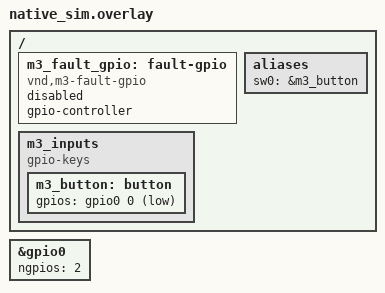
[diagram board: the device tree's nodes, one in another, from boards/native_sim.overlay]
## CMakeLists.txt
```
cmake_minimum_required(VERSION 3.20.0)
find_package(Zephyr REQUIRED HINTS $ENV{ZEPHYR_BASE})
project(crux_m3_native_tests LANGUAGES C)
if(NOT M3_GPIO_SCENARIO MATCHES "^(emulated|missing|fault)$")
    message(FATAL_ERROR "Select an explicit M3_GPIO_SCENARIO")
endif()
target_compile_definitions(app PRIVATE
    M3_EXPECT_MISSING=$<STREQUAL:${M3_GPIO_SCENARIO},missing>
    M3_EXPECT_READ_ERROR=$<STREQUAL:${M3_GPIO_SCENARIO},fault>)
target_sources(app PRIVATE src/main.c src/fault_gpio.c
    ../../samples/controller/core/health.c
    ../../samples/controller/zephyr/device_input.c)
target_include_directories(app PRIVATE ../../samples/controller/include
    ../../samples/controller/zephyr .)
target_compile_options(app PRIVATE -Wall -Wextra -Werror)
```

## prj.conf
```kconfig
CONFIG_STD_C17=y
CONFIG_ZTEST=y
CONFIG_GPIO=y
```

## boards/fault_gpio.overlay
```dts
&m3_fault_gpio {
    status = "okay";
};
&m3_button {
    gpios = <&m3_fault_gpio 0 GPIO_ACTIVE_LOW>;
};
```

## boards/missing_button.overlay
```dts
/ {
    /delete-node/ m3_inputs;
    aliases {
        /delete-property/ sw0;
    };
};
```

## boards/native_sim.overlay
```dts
#include <zephyr/dt-bindings/gpio/gpio.h>

/ {
    m3_fault_gpio: fault-gpio {
        compatible = "vnd,m3-fault-gpio";
        gpio-controller;
        #gpio-cells = <2>;
        status = "disabled";
    };
    aliases {
        sw0 = &m3_button;
    };
    m3_inputs {
        compatible = "gpio-keys";
        m3_button: button {
            gpios = <&gpio0 0 (GPIO_PULL_UP | GPIO_ACTIVE_LOW)>;
        };
    };
};

&gpio0 {
    ngpios = <2>;
};
```

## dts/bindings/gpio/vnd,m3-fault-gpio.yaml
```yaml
description: Test-only GPIO API fixture for a controlled negative native read
compatible: "vnd,m3-fault-gpio"
include: gpio-controller.yaml
gpio-cells:
  - pin
  - flags
```

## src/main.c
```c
#include "controller_health.h"
#include "device_input.h"
#include "fault_gpio.h"

#include <errno.h>
#include <zephyr/drivers/gpio.h>
#include <zephyr/drivers/gpio/gpio_emul.h>
#include <zephyr/ztest.h>

BUILD_ASSERT(DT_NODE_HAS_STATUS(DT_ALIAS(sw0), okay) == !M3_EXPECT_MISSING,
             "GPIO fixture does not match the requested scenario");
BUILD_ASSERT(DT_NODE_HAS_STATUS(DT_NODELABEL(m3_fault_gpio), okay) == M3_EXPECT_READ_ERROR,
             "Read-error fixture does not match the requested scenario");

ZTEST(controller_m3, test_device_contract)
{
    int value = 42;
    zassert_equal(controller_device_read(NULL), -EINVAL);
#if DT_NODE_HAS_STATUS(DT_ALIAS(sw0), okay)
#if DT_NODE_HAS_STATUS(DT_NODELABEL(m3_fault_gpio), okay)
    m3_test_gpio_fail_read(false);
#endif
    zassert_equal(controller_device_init(), 0);
    zassert_equal(controller_device_read(&value), 0);
    zassert_true(value == 0 || value == 1);
#else
    zassert_equal(controller_device_init(), -ENODEV);
    zassert_equal(controller_device_read(&value), -ENODEV);
    zassert_equal(value, 42, "failed read modified caller output");
#endif
}

ZTEST(controller_m3, test_active_low_transitions_or_unavailable)
{
    int value = 42;
#if DT_NODE_HAS_STATUS(DT_ALIAS(sw0), okay)
#if DT_NODE_HAS_STATUS(DT_NODELABEL(m3_fault_gpio), okay)
    m3_test_gpio_fail_read(false);
#else
    const struct gpio_dt_spec button = GPIO_DT_SPEC_GET(DT_ALIAS(sw0), gpios);
#endif
    zassert_equal(controller_device_init(), 0);
    for (int i = 0; i < 20; ++i) {
        int raw = i % 2;
#if DT_NODE_HAS_STATUS(DT_NODELABEL(m3_fault_gpio), okay)
        m3_test_gpio_value(raw);
#else
        zassert_equal(gpio_emul_input_set_dt(&button, raw), 0);
#endif
        zassert_equal(controller_device_read(&value), 0);
        zassert_equal(value, 1 - raw, "active-low conversion is wrong");
    }
#else
    zassert_equal(controller_device_init(), -ENODEV);
    zassert_equal(controller_device_read(&value), -ENODEV);
    zassert_equal(value, 42);
#endif
}

#if DT_NODE_HAS_STATUS(DT_NODELABEL(m3_fault_gpio), okay)
ZTEST(controller_m3, test_native_read_error_preserves_output_then_recovers)
{
    int value = 42;
    zassert_equal(controller_device_init(), 0);
    m3_test_gpio_fail_read(true);
    zassert_equal(controller_device_read(&value), -EIO);
    zassert_equal(value, 42, "underlying driver error corrupted caller output");
    m3_test_gpio_fail_read(false);
    m3_test_gpio_value(0);
    zassert_equal(controller_device_read(&value), 0);
    zassert_equal(value, 1);
}
#endif

ZTEST(controller_m3, test_progress_stall_delayed_observer_and_recovery)
{
    controller_health_t health;
    zassert_true(controller_health_init(&health, 500));
    zassert_false(controller_health_observe(&health, 0, (controller_progress_t){-1, 0, false}));
    zassert_true(controller_health_observe(&health, 100, (controller_progress_t){100, 1, true}));
    zassert_false(controller_health_observe(&health, 601, (controller_progress_t){100, 1, true}));
    zassert_false(controller_health_observe(&health, 2000, (controller_progress_t){200, 2, true}));
    zassert_false(
        controller_health_observe(&health, 2100, (controller_progress_t){2100, 3, false}));
    zassert_false(controller_health_observe(&health, 2200, (controller_progress_t){2100, 3, true}));
    zassert_true(controller_health_observe(&health, 2300, (controller_progress_t){2300, 4, true}));
}

ZTEST(controller_m3, test_required_service_failure_is_not_ready)
{
    zassert_equal(controller_readiness(true, false, true, true), CONTROLLER_NOT_READY);
    zassert_equal(controller_readiness(true, true, false, true), CONTROLLER_NOT_READY);
    zassert_equal(controller_readiness(true, true, true, false), CONTROLLER_DEGRADED);
    zassert_equal(controller_readiness(true, true, true, true), CONTROLLER_READY);
}

ZTEST_SUITE(controller_m3, NULL, NULL, NULL, NULL, NULL);
```

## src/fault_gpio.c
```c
/* This native test fixture supplies an error hook missing from gpio_emul.
 * It is compiled only in tests; no production driver or test control is added. */
#include "fault_gpio.h"

#include <errno.h>
#include <zephyr/drivers/gpio.h>

#if DT_NODE_HAS_STATUS(DT_NODELABEL(m3_fault_gpio), okay)
struct fault_gpio_data {
    struct gpio_driver_data common;
    int raw;
    bool fail_read;
};
static struct fault_gpio_data data = {.raw = 1};
static const struct gpio_driver_config configuration = {.port_pin_mask = BIT(0)};

static int configure(const struct device *port, gpio_pin_t pin, gpio_flags_t flags)
{
    ARG_UNUSED(port);
    if (pin != 0 || !(flags & GPIO_INPUT) || (flags & GPIO_OUTPUT)) {
        return -ENOTSUP;
    }
    return 0;
}

static int read_raw(const struct device *port, gpio_port_value_t *value)
{
    struct fault_gpio_data *state = port->data;
    if (state->fail_read) {
        return -EIO;
    }
    *value = (gpio_port_value_t)state->raw;
    return 0;
}

static DEVICE_API(gpio, fault_api) = {.pin_configure = configure, .port_get_raw = read_raw};
DEVICE_DT_DEFINE(DT_NODELABEL(m3_fault_gpio), NULL, NULL, &data, &configuration, POST_KERNEL,
                 CONFIG_GPIO_INIT_PRIORITY, &fault_api);

void m3_test_gpio_value(int raw)
{
    data.raw = raw;
}
void m3_test_gpio_fail_read(bool fail)
{
    data.fail_read = fail;
}
#endif
```
